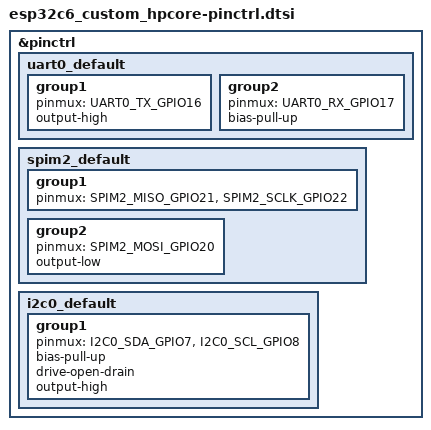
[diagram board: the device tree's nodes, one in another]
/*
 * SPDX-License-Identifier: Apache-2.0
 */

#include <zephyr/dt-bindings/pinctrl/esp-pinctrl-common.h>
#include <dt-bindings/pinctrl/esp32c6-pinctrl.h>
#include <zephyr/dt-bindings/pinctrl/esp32c6-gpio-sigmap.h>

&pinctrl {
	uart0_default: uart0_default {
		group1 {
			pinmux = <UART0_TX_GPIO16>;
			output-high;
		};

		group2 {
			pinmux = <UART0_RX_GPIO17>;
			bias-pull-up;
		};
	};

	spim2_default: spim2_default {
		group1 {
			pinmux = <SPIM2_MISO_GPIO21>,
				 <SPIM2_SCLK_GPIO22>;
		};

		group2 {
			pinmux = <SPIM2_MOSI_GPIO20>;
			output-low;
		};
	};

	i2c0_default: i2c0_default {
		group1 {
			pinmux = <I2C0_SDA_GPIO7>,
				 <I2C0_SCL_GPIO8>;
			bias-pull-up;
			drive-open-drain;
			output-high;
		};
	};
};
